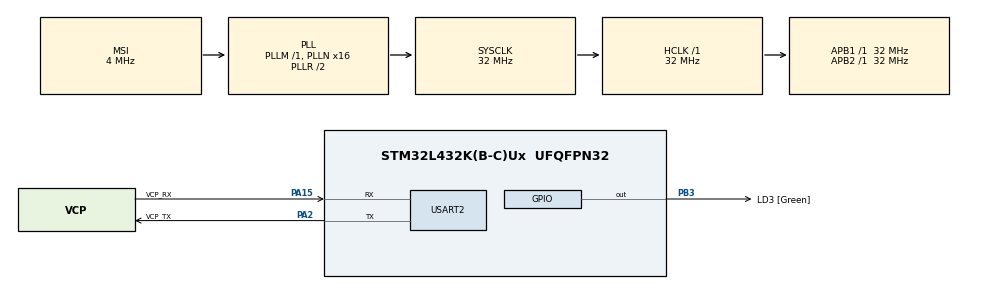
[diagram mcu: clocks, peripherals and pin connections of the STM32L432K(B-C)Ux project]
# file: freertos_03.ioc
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Mcu.Family=STM32L4
RCC.MSI_VALUE=4000000
PA14\ (JTCK-SWCLK).Mode=Serial_Wire
VP_SYS_VS_tim6.Mode=TIM6
RCC.CortexFreq_Value=32000000
FREERTOS.Tasks01=Task01,24,128,StartTask01,Default,NULL,Dynamic,NULL,NULL;Task02,8,128,StartTask01,Default,NULL,Dynamic,NULL,NULL;Task03,8,128,StartTask01,Default,NULL,Dynamic,NULL,NULL;Task04,8,128,StartTask02,Default,NULL,Dynamic,NULL,NULL
NVIC.TIM6_DAC_IRQn=true\:0\:0\:false\:false\:true\:false\:false\:true
PA0.GPIO_Label=MCO [High speed clock in]
PC15-OSC32_OUT\ (PC15).Signal=RCC_OSC32_OUT
PA15\ (JTDI).Signal=USART2_RX
PB3\ (JTDO-TRACESWO).GPIO_Label=LD3 [Green]
PA14\ (JTCK-SWCLK).GPIO_Label=SWCLK
PC15-OSC32_OUT\ (PC15).Mode=LSE-External-Oscillator
NVIC.USART2_IRQn=true\:5\:0\:false\:false\:true\:true\:true\:true
RCC.SYSCLKSource=RCC_SYSCLKSOURCE_PLLCLK
ProjectManager.StackSize=0x400
PB3\ (JTDO-TRACESWO).Signal=GPIO_Output
PC14-OSC32_IN\ (PC14).Mode=LSE-External-Oscillator
VP_FREERTOS_VS_CMSIS_V2.Mode=CMSIS_V2
PA14\ (JTCK-SWCLK).Signal=SYS_JTCK-SWCLK
RCC.HSI16_VALUE=16000000
PA15\ (JTDI).Mode=Asynchronous
ProjectManager.TargetToolchain=STM32CubeIDE
RCC.HCLKFreq_Value=32000000
RCC.APB2TimFreq_Value=32000000
RCC.AHBFreq_Value=32000000
RCC.HSE_VALUE=8000000
board=NUCLEO-L432KC
USART2.VirtualMode-Asynchronous=VM_ASYNC
RCC.VCOOutputFreq_Value=64000000
RCC.PLLMUL=RCC_PLLMUL_4
RCC.APB2Freq_Value=32000000
PA13\ (JTMS-SWDIO).GPIO_Label=SWDIO
PA0.Mode=HSE-External-Clock-Source-for-LittleOrca
PA15\ (JTDI).GPIO_Label=VCP_RX
Mcu.Name=STM32L432K(B-C)Ux
PA2.Signal=USART2_TX
PA0.Signal=RCC_CK_IN
PA13\ (JTMS-SWDIO).Mode=Serial_Wire
RCC.SYSCLKFreq_VALUE=32000000
Mcu.Package=UFQFPN32
NVIC.TimeBase=TIM6_DAC_IRQn
PC14-OSC32_IN\ (PC14).Signal=RCC_OSC32_IN
PA2.GPIO_Label=VCP_TX
NVIC.TimeBaseIP=TIM6
ProjectManager.HeapSize=0x200
RCC.HSI_VALUE=16000000
NVIC.PriorityGroup=NVIC_PRIORITYGROUP_4
RCC.PLLN=16
RCC.APB1TimFreq_Value=32000000
PA2.Mode=Asynchronous
PA13\ (JTMS-SWDIO).Signal=SYS_JTMS-SWDIO
RCC.APB1Freq_Value=32000000
RCC.HSI48_VALUE=48000000

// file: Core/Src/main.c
/* USER CODE BEGIN Header */
/**
  ******************************************************************************
  * @file           : main.c
  * @brief          : Main program body
  ******************************************************************************
  * @attention
  *
  * <h2><center>&copy; Copyright (c) 2021 STMicroelectronics.
  * All rights reserved.</center></h2>
  *
  * This software component is licensed by ST under BSD 3-Clause license,
  * the "License"; You may not use this file except in compliance with the
  * License. You may obtain a copy of the License at:
  *                        opensource.org/licenses/BSD-3-Clause
  *
  ******************************************************************************
  */
/* USER CODE END Header */
#include "main.h"
#include "cmsis_os.h"

/* USER CODE BEGIN Includes */
#include "retarget.h"
#include <stdio.h>
#include <string.h>
/* USER CODE END Includes */

UART_HandleTypeDef huart2;

/* Definitions for Task01 */
osThreadId_t Task01Handle;
const osThreadAttr_t Task01_attributes = {
  .name = "Task01",
  .stack_size = 128 * 4,
  .priority = (osPriority_t) osPriorityNormal,
};
/* Definitions for Task02 */
osThreadId_t Task02Handle;
const osThreadAttr_t Task02_attributes = {
  .name = "Task02",
  .stack_size = 128 * 4,
  .priority = (osPriority_t) osPriorityLow,
};
/* Definitions for Task03 */
osThreadId_t Task03Handle;
const osThreadAttr_t Task03_attributes = {
  .name = "Task03",
  .stack_size = 128 * 4,
  .priority = (osPriority_t) osPriorityLow,
};
/* Definitions for Task04 */
osThreadId_t Task04Handle;
const osThreadAttr_t Task04_attributes = {
  .name = "Task04",
  .stack_size = 128 * 4,
  .priority = (osPriority_t) osPriorityLow,
};
/* USER CODE BEGIN PV */
unsigned int tick = 0;
/* USER CODE END PV */

void SystemClock_Config(void);
static void MX_GPIO_Init(void);
static void MX_USART2_UART_Init(void);
void StartTask01(void *argument);
void StartTask02(void *argument);

int main(void)
{

  /* MCU Configuration--------------------------------------------------------*/

  /* Reset of all peripherals, Initializes the Flash interface and the Systick. */
  HAL_Init();

  /* Configure the system clock */
  SystemClock_Config();

  /* Initialize all configured peripherals */
  MX_GPIO_Init();
  MX_USART2_UART_Init();
  /* USER CODE BEGIN 2 */
  RetargetInit(&huart2);
  printf("\n---- beginning ----\n\n");
  HAL_GPIO_WritePin(LD3_GPIO_Port, LD3_Pin, GPIO_PIN_SET);
  /* USER CODE END 2 */

  /* Init scheduler */
  osKernelInitialize();

  /* Create the thread(s) */
  /* creation of Task01 */
  Task01Handle = osThreadNew(StartTask01, (void*)1, &Task01_attributes);

  /* creation of Task02 */
  Task02Handle = osThreadNew(StartTask01, (void*)2, &Task02_attributes);

  /* creation of Task03 */
  Task03Handle = osThreadNew(StartTask01, (void*)3, &Task03_attributes);

  /* creation of Task04 */
  Task04Handle = osThreadNew(StartTask02, (void*)4, &Task04_attributes);

  /* Start scheduler */
  osKernelStart();

  /* We should never get here as control is now taken by the scheduler */
  /* Infinite loop */
  while (1)
  {

  }
}

void SystemClock_Config(void)
{
  RCC_OscInitTypeDef RCC_OscInitStruct = {0};
  RCC_ClkInitTypeDef RCC_ClkInitStruct = {0};
  RCC_PeriphCLKInitTypeDef PeriphClkInit = {0};

  /** Configure LSE Drive Capability
  */
  HAL_PWR_EnableBkUpAccess();
  __HAL_RCC_LSEDRIVE_CONFIG(RCC_LSEDRIVE_LOW);
  /** Initializes the RCC Oscillators according to the specified parameters
  * in the RCC_OscInitTypeDef structure.
  */
  RCC_OscInitStruct.OscillatorType = RCC_OSCILLATORTYPE_LSE|RCC_OSCILLATORTYPE_MSI;
  RCC_OscInitStruct.LSEState = RCC_LSE_ON;
  RCC_OscInitStruct.MSIState = RCC_MSI_ON;
  RCC_OscInitStruct.MSICalibrationValue = 0;
  RCC_OscInitStruct.MSIClockRange = RCC_MSIRANGE_6;
  RCC_OscInitStruct.PLL.PLLState = RCC_PLL_ON;
  RCC_OscInitStruct.PLL.PLLSource = RCC_PLLSOURCE_MSI;
  RCC_OscInitStruct.PLL.PLLM = 1;
  RCC_OscInitStruct.PLL.PLLN = 16;
  RCC_OscInitStruct.PLL.PLLP = RCC_PLLP_DIV7;
  RCC_OscInitStruct.PLL.PLLQ = RCC_PLLQ_DIV2;
  RCC_OscInitStruct.PLL.PLLR = RCC_PLLR_DIV2;
  if (HAL_RCC_OscConfig(&RCC_OscInitStruct) != HAL_OK)
  {
    Error_Handler();
  }
  /** Initializes the CPU, AHB and APB buses clocks
  */
  RCC_ClkInitStruct.ClockType = RCC_CLOCKTYPE_HCLK|RCC_CLOCKTYPE_SYSCLK
                              |RCC_CLOCKTYPE_PCLK1|RCC_CLOCKTYPE_PCLK2;
  RCC_ClkInitStruct.SYSCLKSource = RCC_SYSCLKSOURCE_PLLCLK;
  RCC_ClkInitStruct.AHBCLKDivider = RCC_SYSCLK_DIV1;
  RCC_ClkInitStruct.APB1CLKDivider = RCC_HCLK_DIV1;
  RCC_ClkInitStruct.APB2CLKDivider = RCC_HCLK_DIV1;

  if (HAL_RCC_ClockConfig(&RCC_ClkInitStruct, FLASH_LATENCY_1) != HAL_OK)
  {
    Error_Handler();
  }
  PeriphClkInit.PeriphClockSelection = RCC_PERIPHCLK_USART2;
  PeriphClkInit.Usart2ClockSelection = RCC_USART2CLKSOURCE_PCLK1;
  if (HAL_RCCEx_PeriphCLKConfig(&PeriphClkInit) != HAL_OK)
  {
    Error_Handler();
  }
  /** Configure the main internal regulator output voltage
  */
  if (HAL_PWREx_ControlVoltageScaling(PWR_REGULATOR_VOLTAGE_SCALE1) != HAL_OK)
  {
    Error_Handler();
  }
  /** Enable MSI Auto calibration
  */
  HAL_RCCEx_EnableMSIPLLMode();
}

static void MX_USART2_UART_Init(void)
{

  huart2.Instance = USART2;
  huart2.Init.BaudRate = 115200;
  huart2.Init.WordLength = UART_WORDLENGTH_8B;
  huart2.Init.StopBits = UART_STOPBITS_1;
  huart2.Init.Parity = UART_PARITY_NONE;
  huart2.Init.Mode = UART_MODE_TX_RX;
  huart2.Init.HwFlowCtl = UART_HWCONTROL_NONE;
  huart2.Init.OverSampling = UART_OVERSAMPLING_16;
  huart2.Init.OneBitSampling = UART_ONE_BIT_SAMPLE_DISABLE;
  huart2.AdvancedInit.AdvFeatureInit = UART_ADVFEATURE_NO_INIT;
  if (HAL_UART_Init(&huart2) != HAL_OK)
  {
    Error_Handler();
  }

}

static void MX_GPIO_Init(void)
{
  GPIO_InitTypeDef GPIO_InitStruct = {0};

  /* GPIO Ports Clock Enable */
  __HAL_RCC_GPIOC_CLK_ENABLE();
  __HAL_RCC_GPIOA_CLK_ENABLE();
  __HAL_RCC_GPIOB_CLK_ENABLE();

  /*Configure GPIO pin Output Level */
  HAL_GPIO_WritePin(LD3_GPIO_Port, LD3_Pin, GPIO_PIN_RESET);

  /*Configure GPIO pin : LD3_Pin */
  GPIO_InitStruct.Pin = LD3_Pin;
  GPIO_InitStruct.Mode = GPIO_MODE_OUTPUT_PP;
  GPIO_InitStruct.Pull = GPIO_NOPULL;
  GPIO_InitStruct.Speed = GPIO_SPEED_FREQ_LOW;
  HAL_GPIO_Init(LD3_GPIO_Port, &GPIO_InitStruct);

}

/* USER CODE BEGIN 4 */

static int counter = 0;

void stackfunction(int stack)
{
	stack--;
	if(stack > 0){
		stackfunction(stack);
	}
	else{
		return;
	}
}

/* USER CODE END 4 */

void StartTask01(void *argument)
{
  /* USER CODE BEGIN 5 */
  /* Infinite loop */
  for(;;)
  {
	  counter++;
	  pvPortMalloc((int)argument);
	  stackfunction(counter);
	  osDelay(50*((int)argument));

  }
  /* USER CODE END 5 */
}

void StartTask02(void *argument)
{
  /* USER CODE BEGIN StartTask02 */
  /* Infinite loop */
  for(;;)
  {
    printf("1: stack size: %lu\n", uxTaskGetStackHighWaterMark(Task01Handle));
    printf("2: stack size: %lu\n", uxTaskGetStackHighWaterMark(Task02Handle));
    printf("3: stack size: %lu\n", uxTaskGetStackHighWaterMark(Task03Handle));
    printf("X: heap left:  %u\n",  xPortGetFreeHeapSize());
	osDelay(200);
  }
  /* USER CODE END StartTask02 */
}

 /**
  * @brief  Period elapsed callback in non blocking mode
  * @note   This function is called  when TIM6 interrupt took place, inside
  * HAL_TIM_IRQHandler(). It makes a direct call to HAL_IncTick() to increment
  * a global variable "uwTick" used as application time base.
  * @param  htim : TIM handle
  * @retval None
  */
void HAL_TIM_PeriodElapsedCallback(TIM_HandleTypeDef *htim)
{
  if (htim->Instance == TIM6) {
    HAL_IncTick();
  }
}

void Error_Handler(void)
{
  __disable_irq();
  while (1)
  {
  }
}

/************************ (C) COPYRIGHT STMicroelectronics *****END OF FILE****/
